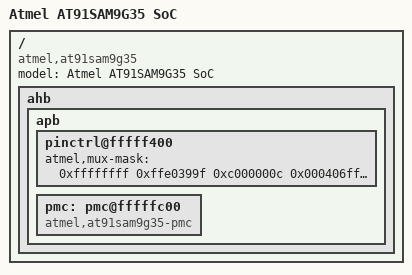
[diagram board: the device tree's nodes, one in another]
/* bench 11750.2.0 6fa54b86c21c */
/* bench 11750.2.1 7a15af52b9f7 */
/* bench 11750.2.2 b31652396638 */
/*
 * at91sam9g35.dtsi - Device Tree Include file for AT91SAM9G35 SoC
 *
 * Copyright (C) 2012 Jean-Christophe PLAGNIOL-VILLARD <plagnioj@jcrosoft.com>
 */

#include "at91sam9x5.dtsi"
#include "at91sam9x5_lcd.dtsi"
#include "at91sam9x5_macb0.dtsi"

/ {
	model = "Atmel AT91SAM9G35 SoC";
	compatible = "atmel,at91sam9g35", "atmel,at91sam9x5";

/* bench 26589.1.0 9ba6848b194a */
/* bench 26589.1.1 c2b2b291e909 */
/* bench 26589.1.2 2218e1914165 */
/* bench 26589.1.3 48fe7951ebaa */
/* bench 26589.1.4 7b1f72b24312 */
/* bench 27666.1.0 6fd1282a290d */
/* bench 27666.1.1 1e2914b2e56e */
/* bench 27666.1.2 26d6d400a9bc */
/* bench 27666.1.3 80c4c73b2cc0 */
/* bench 27666.1.4 35c97d42291a */
/* bench 27666.1.5 0a6ff525ba02 */
/* bench 27666.1.6 2bc65aee1335 */
/* bench 27666.1.7 bbcece1368a5 */
/* bench 27666.1.8 eac8f2bc2bc2 */
/* bench 27666.1.9 513b66ef0be9 */
/* bench 27666.1.10 d0e8beca8866 */
/* bench 27666.1.11 55d6811d4ac1 */
/* bench 27666.1.12 3ff5aedf2d64 */
/* bench 26589.1.7 8617cc3147d1 */
	ahb {
		apb {
			pinctrl@fffff400 {
				atmel,mux-mask = <
				      /*    A         B          C     */
				       0xffffffff 0xffe0399f 0xc000000c  /* pioA */
				       0x000406ff 0x00047e3f 0x00000000  /* pioB */
				       0xfdffffff 0x00000000 0xb83fffff  /* pioC */
				       0x003fffff 0x003f8000 0x00000000  /* pioD */
				      >;
			};

			pmc: pmc@fffffc00 {
				compatible = "atmel,at91sam9g35-pmc", "atmel,at91sam9x5-pmc", "syscon";
			};
		};
	};
};
